# STM32WB55 register map
File version: 2.0
CPU: CM4 r0p1, little endian, MPU, FPU, 4 interrupt priority bits
Registers are 32-bit, read-write, reset 0x0 unless marked. A register's access mark holds for its fields unless they carry their own. Offsets are from the block's base; [hi:lo] are bit positions; {n}, {i} and the like mark numbered series.

## AES1 — Advanced encryption standard hardware accelerator 1
Base 0x50060000
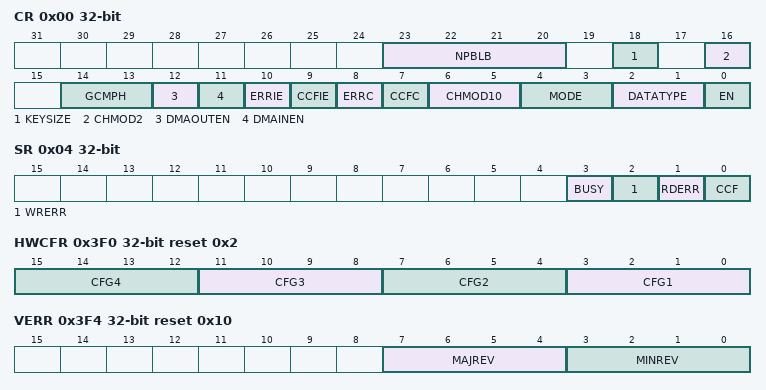
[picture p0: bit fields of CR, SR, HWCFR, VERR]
0x00 CR — control register
  [23:20] NPBLB — Number of padding bytes in last block of payload
  [18] KEYSIZE — Key size selection
    0=AES128 (128); 1=AES256 (256)
  [16] CHMOD2 — AES chaining mode Bit2
    0=CHMOD (Mode as per CHMOD (ECB, CBC, CTR, GCM)); 1=CCM (Counter with CBC-MAC (CCM) - CHMOD must be 0 (ECB))
  [14:13] GCMPH — Used only for GCM, CCM and GMAC algorithms and has no effect when other algorithms are selected
    0=Init phase; 1=Header phase; 2=Payload phase; 3=Final Phase
  [12] DMAOUTEN — Enable DMA management of data output phase
    0=Disable DMA Output; 1=Enabled DMA Output
  [11] DMAINEN — Enable DMA management of data input phase
    0=Disable DMA Input; 1=Enable DMA Input
  [10] ERRIE — Error interrupt enable
    0=Disabled (Disable (mask) error interrupt); 1=Enabled (Enable error interrupt)
  [9] CCFIE — CCF flag interrupt enable
    0=Disabled (Disable (mask) CCF interrupt); 1=Enabled (Enable CCF interrupt)
  [8] ERRC — Error clear
    on write: 1=Clear RDERR and WRERR flags
  [7] CCFC — Computation Complete Flag Clear
    on write: 1=Clear computation complete flag
  [6:5] CHMOD10 — AES chaining mode Bit1 Bit0
    0=ECB (Electronic codebook (ECB) / Counter with CBC-MAC (CCM) if CHMOD2 is 1); 1=CBC (Cipher-block chaining (CBC)); 2=CTR (Counter mode (CTR)); 3=GCM (Galois counter mode (GCM) and Galois message authentication code (GMAC))
  [4:3] MODE — AES operating mode
    0=Mode 1: encryption; 1=Mode 2: key derivation (or key preparation for ECB/CBC decryption); 2=Mode 3: decryption; 3=Mode 4: key derivation then single decryption
  [2:1] DATATYPE — Data type selection (for data in and data out to/from the cryptographic block)
    0=None (Word); 1=Half-word (16-bit); 2=Byte (8-bit); 3=Bit
  [0] EN — AES enable
    0=Disabled (Disable AES); 1=Enabled (Enable AES)
0x04 SR ro — status register
  [3] BUSY — Busy flag
    0=Idle; 1=Busy
  [2] WRERR — Write error flag
    0=NoError (Write error not detected); 1=Error (Write error detected)
  [1] RDERR — Read error flag
    0=NoError (Read error not detected); 1=Error (Read error detected)
  [0] CCF — Computation complete flag
    0=Complete (Computation complete); 1=NotComplete (Computation not complete)
0x08 DINR — data input register
  [31:0] DIN — Data Input Register
0x0C DOUTR ro — data output register
  [31:0] DOUT — Data output register
0x10 KEYR0 — key register 0
  [31:0] KEY — Data Output Register (LSB key [31:0])
0x14 KEYR1 — key register 1
  [31:0] KEY — AES key register (key [63:32])
0x18 KEYR2 — key register 2
  [31:0] KEY — AES key register (key [95:64])
0x1C KEYR3 — key register 3
  [31:0] KEY — AES key register (MSB key [127:96])
0x20 IVR0 — initialization vector register 0
  [31:0] IVI — initialization vector register (LSB IVR [31:0])
0x24 IVR1 — initialization vector register 1
  [31:0] IVI — Initialization Vector Register (IVR [63:32])
0x28 IVR2 — initialization vector register 2
  [31:0] IVI — Initialization Vector Register (IVR [95:64])
0x2C IVR3 — initialization vector register 3
  [31:0] IVI — Initialization Vector Register (MSB IVR [127:96])
{0x20+4i} KEYR{i} (i=4..7) — key register {i}
  [31:0] KEY — AES key register (MSB key [{32i+31}:{32i}])
{0x40+4i} SUSP{i}R (i=0..7) — AES suspend register {i}
  [31:0] SUSP
0x3F0 HWCFR ro reset 0x2 — AES hardware configuration register
  [4n-1:4n-4] CFG{n} (n=1..4) — HW Generic {n}
0x3F4 VERR ro reset 0x10 — AES version register
  [7:4] MAJREV — Major revision
  [3:0] MINREV — Minor revision
0x3F8 IPIDR ro reset 0x170023 — AES identification register
  [31:0] ID — Identification code
0x3FC SIDR ro reset 0xA3C5DD01 — AES size ID register
  [31:0] ID — Size Identification code

## AES2 — Advanced encryption standard hardware accelerator 1
Base 0x58001800
Registers as AES1, without HWCFR, VERR, IPIDR, SIDR; these are added or differ:
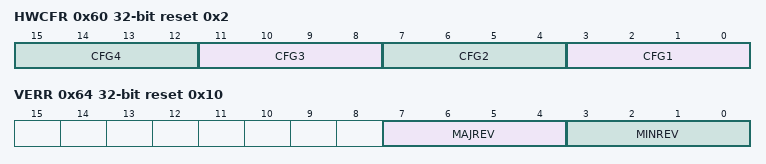
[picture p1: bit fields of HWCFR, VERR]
0x60 HWCFR ro reset 0x2 — AES hardware configuration register
  [4n-1:4n-4] CFG{n} (n=1..4) — HW Generic {n}
0x64 VERR ro reset 0x10 — AES version register
  [7:4] MAJREV — Major revision
  [3:0] MINREV — Minor revision
0x68 IPIDR ro reset 0x170023 — AES identification register
  [31:0] ID — Identification code
0x6C SIDR ro reset 0x170023 — AES size ID register
  [31:0] ID — Size Identification code
